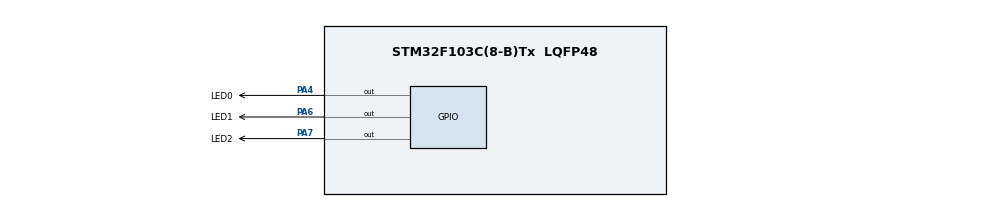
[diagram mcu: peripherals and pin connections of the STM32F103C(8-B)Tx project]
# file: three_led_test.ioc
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Mcu.Family=STM32F1
Mcu.Name=STM32F103C(8-B)Tx
Mcu.Package=LQFP48
NVIC.PriorityGroup=NVIC_PRIORITYGROUP_4
PA13.Mode=Serial_Wire
PA13.Signal=SYS_JTMS-SWDIO
PA14.Mode=Serial_Wire
PA14.Signal=SYS_JTCK-SWCLK
PA4.GPIO_Label=LED0
PA4.GPIO_ModeDefaultOutputPP=GPIO_MODE_OUTPUT_PP
PA4.Signal=GPIO_Output
PA6.GPIO_Label=LED1
PA6.GPIO_ModeDefaultOutputPP=GPIO_MODE_OUTPUT_PP
PA6.GPIO_Speed=GPIO_SPEED_FREQ_HIGH
PA6.Signal=GPIO_Output
PA7.GPIO_Label=LED2
PA7.GPIO_ModeDefaultOutputPP=GPIO_MODE_OUTPUT_PP
PA7.GPIO_Speed=GPIO_SPEED_FREQ_HIGH
PA7.Signal=GPIO_Output
PD0-OSC_IN.Mode=HSE-External-Clock-Source
PD0-OSC_IN.Signal=RCC_OSC_IN
PD1-OSC_OUT.Mode=HSE-External-Clock-Source
PD1-OSC_OUT.Signal=RCC_OSC_OUT
ProjectManager.HeapSize=0x200
ProjectManager.StackSize=0x400
ProjectManager.TargetToolchain=STM32CubeIDE
RCC.APB1Freq_Value=8000000
RCC.APB2Freq_Value=8000000
RCC.PLLSourceVirtual=RCC_PLLSOURCE_HSE
RCC.USBFreq_Value=16000000
board=custom

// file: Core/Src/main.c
/* USER CODE BEGIN Header */
/**
  ******************************************************************************
  * @file           : main.c
  * @brief          : Main program body
  ******************************************************************************
  * @attention
  *
  * Copyright (c) 2026 STMicroelectronics.
  * All rights reserved.
  *
  * This software is licensed under terms that can be found in the LICENSE file
  * in the root directory of this software component.
  * If no LICENSE file comes with this software, it is provided AS-IS.
  *
  ******************************************************************************
  */
/* USER CODE END Header */
#include "main.h"
#include "gpio.h"

/* USER CODE BEGIN PD */
/* USER CODE BEGIN PD */
#define LED_ON  GPIO_PIN_SET
#define LED_OFF GPIO_PIN_RESET
/* USER CODE END PD */
/* USER CODE END PD */

void SystemClock_Config(void);

int main(void)
{

  /* MCU Configuration--------------------------------------------------------*/

  /* Reset of all peripherals, Initializes the Flash interface and the Systick. */
  HAL_Init();

  /* Configure the system clock */
  SystemClock_Config();

  /* Initialize all configured peripherals */
  MX_GPIO_Init();
  /* USER CODE BEGIN 2 */
  uint32_t last_tick = HAL_GetTick();
  uint8_t led_step = 0;
  /* USER CODE END 2 */

  /* Infinite loop */
  while (1)
  {
    uint32_t now = HAL_GetTick();

    if ((now - last_tick) >= 500U)
    {
      last_tick = now;

      led_step++;
      if (led_step >= 3U)
      {
        led_step = 0U;
      }
    }

    HAL_GPIO_WritePin(LED0_GPIO_Port, LED0_Pin,
        (led_step == 0U) ? GPIO_PIN_RESET : GPIO_PIN_SET);

    HAL_GPIO_WritePin(LED1_GPIO_Port, LED1_Pin,
        (led_step == 1U) ? GPIO_PIN_RESET : GPIO_PIN_SET);

    HAL_GPIO_WritePin(LED2_GPIO_Port, LED2_Pin,
        (led_step == 2U) ? GPIO_PIN_RESET : GPIO_PIN_SET);
  }
}

void SystemClock_Config(void)
{
  RCC_OscInitTypeDef RCC_OscInitStruct = {0};
  RCC_ClkInitTypeDef RCC_ClkInitStruct = {0};

  /** Initializes the RCC Oscillators according to the specified parameters
  * in the RCC_OscInitTypeDef structure.
  */
  RCC_OscInitStruct.OscillatorType = RCC_OSCILLATORTYPE_HSI;
  RCC_OscInitStruct.HSIState = RCC_HSI_ON;
  RCC_OscInitStruct.HSICalibrationValue = RCC_HSICALIBRATION_DEFAULT;
  RCC_OscInitStruct.PLL.PLLState = RCC_PLL_NONE;
  if (HAL_RCC_OscConfig(&RCC_OscInitStruct) != HAL_OK)
  {
    Error_Handler();
  }

  /** Initializes the CPU, AHB and APB buses clocks
  */
  RCC_ClkInitStruct.ClockType = RCC_CLOCKTYPE_HCLK|RCC_CLOCKTYPE_SYSCLK
                              |RCC_CLOCKTYPE_PCLK1|RCC_CLOCKTYPE_PCLK2;
  RCC_ClkInitStruct.SYSCLKSource = RCC_SYSCLKSOURCE_HSI;
  RCC_ClkInitStruct.AHBCLKDivider = RCC_SYSCLK_DIV1;
  RCC_ClkInitStruct.APB1CLKDivider = RCC_HCLK_DIV1;
  RCC_ClkInitStruct.APB2CLKDivider = RCC_HCLK_DIV1;

  if (HAL_RCC_ClockConfig(&RCC_ClkInitStruct, FLASH_LATENCY_0) != HAL_OK)
  {
    Error_Handler();
  }
}

void Error_Handler(void)
{
  __disable_irq();
  while (1)
  {
  }
}
